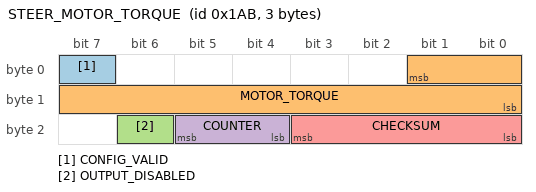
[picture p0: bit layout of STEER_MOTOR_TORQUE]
BO_ 427 STEER_MOTOR_TORQUE: 3 EPS
 SG_ CONFIG_VALID : 7|1@0+ (1,0) [0|1] "" EON
 SG_ MOTOR_TORQUE : 1|10@0+ (1,0) [0|256] "" EON
 SG_ OUTPUT_DISABLED : 22|1@0+ (1,0) [0|1] "" EON
 SG_ COUNTER : 21|2@0+ (1,0) [0|3] "" EON
 SG_ CHECKSUM : 19|4@0+ (1,0) [0|15] "" EON
